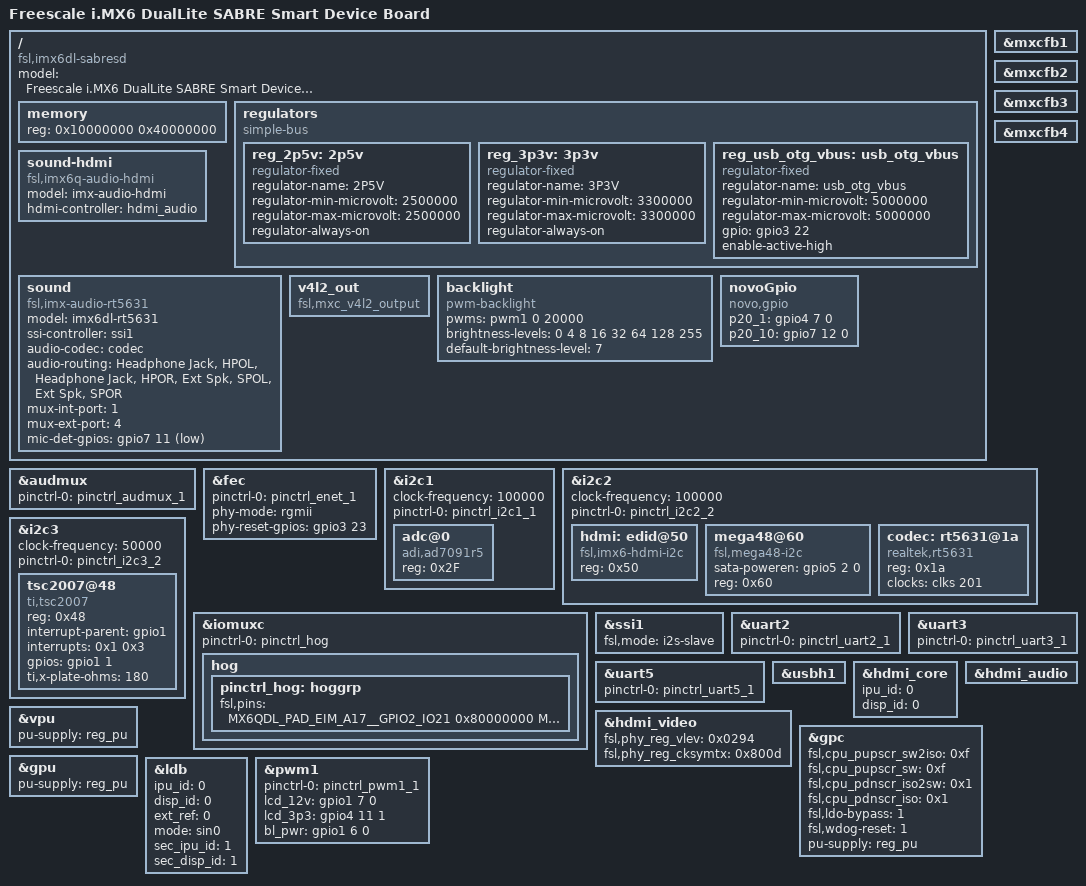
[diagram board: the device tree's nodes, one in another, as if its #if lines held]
/*
 * Copyright (C) 2013 Freescale Semiconductor, Inc.
 *
 * This program is free software; you can redistribute it and/or modify
 * it under the terms of the GNU General Public License version 2 as
 * published by the Free Software Foundation.
 */

/dts-v1/;

#include "hio-novo-dl.dtsi"
#include "hio-novo-qdl-sabresd.dtsi"

/ {
	model = "Freescale i.MX6 DualLite SABRE Smart Device Board";
	compatible = "fsl,imx6dl-sabresd", "fsl,imx6dl";

	memory {
		reg = <0x10000000 0x40000000>;
	};

        regulators {    
                compatible = "simple-bus";

                reg_2p5v: 2p5v {
                        compatible = "regulator-fixed";
                        regulator-name = "2P5V";
                        regulator-min-microvolt = <2500000>;
                        regulator-max-microvolt = <2500000>;
                        regulator-always-on;
                };

		reg_3p3v: 3p3v {
			compatible = "regulator-fixed";
			regulator-name = "3P3V";
			regulator-min-microvolt = <3300000>;
			regulator-max-microvolt = <3300000>;
			regulator-always-on;
		};

		reg_usb_otg_vbus: usb_otg_vbus {
			compatible = "regulator-fixed";
			regulator-name = "usb_otg_vbus";
			regulator-min-microvolt = <5000000>;
			regulator-max-microvolt = <5000000>;
			gpio = <&gpio3 22 0>;
			enable-active-high;
		};
	};
	sound-hdmi {
		compatible = "fsl,imx6q-audio-hdmi",
			     "fsl,imx-audio-hdmi";
		model = "imx-audio-hdmi";
		hdmi-controller = <&hdmi_audio>;
	};
	sound {
		compatible = "fsl,imx-audio-rt5631";
		model = "imx6dl-rt5631";
		ssi-controller = <&ssi1>;
		audio-codec = <&codec>;
		audio-routing =
			"Headphone Jack", "HPOL",
			"Headphone Jack", "HPOR",
			"Ext Spk", "SPOL",
			"Ext Spk", "SPOR";
			//"MICBIAS", "AMIC",
			//"IN3R", "MICBIAS",
			//"DMIC", "MICBIAS",
			//"DMICDAT", "DMIC";
		mux-int-port = <1>;
		mux-ext-port = <4>;
		/*hp-det-gpios = <&gpio7 8 1>;*/
		/*+++wwj begin 20150317@add mic detect*/
		#ifdef CONFIG_MIC_DEC
	              mic-det-gpios = <&gpio7 11 1>;
		#endif
		/*+++wwj end 20150317@add mic detect*/
	};
	/*
	sound {
		compatible = "fsl,imx6q-sabrelite-sgtl5000",
			     "fsl,imx-audio-sgtl5000";
		model = "imx6q-sabrelite-sgtl5000";
		ssi-controller = <&ssi1>;
		audio-codec = <&codec>;
		audio-routing =
			"MIC_IN", "Mic Jack",
			"Mic Jack", "Mic Bias",
			"Headphone Jack", "HP_OUT";
		mux-int-port = <1>;
		mux-ext-port = <4>;
	};
	*/
	v4l2_out {
		compatible = "fsl,mxc_v4l2_output";
		status = "okay";
	};
	backlight {
		compatible = "pwm-backlight";
		/*pwms = <&pwm1 0 5000000>;*/
		pwms = <&pwm1 0 20000>;
		brightness-levels = <0 4 8 16 32 64 128 255>;
		default-brightness-level = <7>;
	};

//+++MQ
	/*
    ds28e10 {
        compatible = "fsl,imx_ds28e10";
        status = "okay";
        ds28e10_io = <&gpio1 2 0>;
    };
	*/
//+++MQ

	//novo_gpio
    novoGpio {
        compatible = "novo,gpio";
        status = "okay";
    
        p20_1 = <&gpio4 7 0>;
		
		//out
		p20_10 = <&gpio7 12 0>;
	};
};

&audmux {
        status = "okay";
        pinctrl-names = "default";
        pinctrl-0 = <&pinctrl_audmux_1>;
};

&mxcfb1 {
        status = "okay";
};

&mxcfb2 {
        status = "okay";
};

&mxcfb3 {
        status = "okay";
};

&mxcfb4 {
        status = "okay";
};

#if 0
&ecspi1 {
	fsl,spi-num-chipselects = <1>;
	cs-gpios = <&gpio4 9 0>,
		    <&gpio4 10 0>;
	pinctrl-names = "default";
	pinctrl-0 = <&pinctrl_ecspi1_2>;
	status = "okay";

	flash: m25p80@0 {
		compatible = "sst,sst25vf016b";
		spi-max-frequency = <20000000>;
		reg = <0>;
	};
};
#endif

&fec {
	pinctrl-names = "default";
	pinctrl-0 = <&pinctrl_enet_1>;
	phy-mode = "rgmii";
	phy-reset-gpios = <&gpio3 23 0>;
	status = "okay";
};

&i2c1 {
	status = "okay";
	clock-frequency = <100000>;
	pinctrl-names = "default";
	pinctrl-0 = <&pinctrl_i2c1_1>;

	adc@0 {
		compatible = "adi,ad7091r5";
		reg = <0x2F>;
	};
};

&i2c2 {
	clock-frequency = <100000>;
	pinctrl-names = "default";
	pinctrl-0 = <&pinctrl_i2c2_2>;
	status = "okay";

	hdmi: edid@50 {
		compatible = "fsl,imx6-hdmi-i2c";
		reg = <0x50>;
	};

	mega48@60 {
		compatible = "fsl,mega48-i2c";
		sata-poweren=<&gpio5 2 0>;
		reg = <0x60>;
	};

	codec: rt5631@1a {
		  compatible = "realtek,rt5631";
		  //compatible = "realtek,alc5631";
		  reg = <0x1a>;
		  clocks = <&clks 201>;
	};
};

&i2c3 {
	status = "okay";
	clock-frequency = <50000>;
	pinctrl-names = "default";
	pinctrl-0 = <&pinctrl_i2c3_2>;

	tsc2007@48 {
    	compatible = "ti,tsc2007";
        reg = <0x48>;
		interrupt-parent = <&gpio1>;
		interrupts = <0x1 0x3>;
		gpios = <&gpio1 1 0>;
		ti,x-plate-ohms = <180>;
		//ti,x-plate-ohms = <400>; 

		//test
		//gpio1 = <&gpio4 7 0>;       
	};
};

&iomuxc {
	pinctrl-names = "default";
	pinctrl-0 = <&pinctrl_hog>;

	hog {
		pinctrl_hog: hoggrp {
			fsl,pins = <
				/* MAX17135 */
				MX6QDL_PAD_EIM_A17__GPIO2_IO21 0x80000000
				MX6QDL_PAD_EIM_D17__GPIO3_IO17 0x80000000
				MX6QDL_PAD_EIM_D20__GPIO3_IO20 0x80000000
				MX6QDL_PAD_EIM_A18__GPIO2_IO20 0x80000000
				MX6QDL_PAD_EIM_OE__GPIO2_IO25 0x80000000
				/* elan touch */
				MX6QDL_PAD_EIM_A20__GPIO2_IO18 0x80000000
				MX6QDL_PAD_EIM_DA8__GPIO3_IO08 0x80000000
				MX6QDL_PAD_GPIO_4__GPIO1_IO04  0x80000000
				/*MX6QDL_PAD_GPIO_1__GPIO1_IO01  0x170b0*/		
				/*MX6QDL_PAD_EIM_D24__UART3_TX_DATA 0x80000000 */
				/*MX6QDL_PAD_EIM_D25__UART3_RX_DATA 0x80000000 */
				/*+++ wangwenjing*/
				MX6QDL_PAD_EIM_A25__GPIO5_IO02 0x80000000
				MX6QDL_PAD_GPIO_1__GPIO1_IO01	0x80000000

				//ad rst
				MX6QDL_PAD_GPIO_3__GPIO1_IO03	0x80000000

				//p20
				MX6QDL_PAD_KEY_COL0__GPIO4_IO06	0x80000000			/*in-p20_1*/
				MX6QDL_PAD_KEY_COL1__GPIO4_IO08	0x80000000			/*in-p20_3*/
				MX6QDL_PAD_KEY_COL2__GPIO4_IO10 0x80000000          /*in-p20_5*/

				MX6QDL_PAD_GPIO_17__GPIO7_IO12	0x80000000			/*out-p20_10*/
				MX6QDL_PAD_CSI0_DAT18__GPIO6_IO04	0x80000000		/*out-p20_12*/				
				MX6QDL_PAD_CSI0_DAT8__GPIO5_IO26	0x80000000		/*out-p20_14*/

				MX6QDL_PAD_KEY_ROW0__GPIO4_IO07		0x80000000		/*in-p20_15*/
				MX6QDL_PAD_KEY_ROW1__GPIO4_IO09		0x80000000		/*in-p20_17*/
				MX6QDL_PAD_KEY_ROW2__GPIO4_IO11		0x80000000		/*in-p20_19*/
				
				MX6QDL_PAD_CSI0_DAT19__GPIO6_IO05	0x80000000		/*out-p20_20*/
				MX6QDL_PAD_CSI0_DAT9__GPIO5_IO27	0x80000000		/*out-p20_21*/
				MX6QDL_PAD_CSI0_DAT10__GPIO5_IO28	0x80000000		/*out-p20_22*/
				MX6QDL_PAD_CSI0_DAT11__GPIO5_IO29	0x80000000		/*out-p20_23*/
				
				//p24
				MX6QDL_PAD_GPIO_19__GPIO4_IO05		0x80000000		/*out-p24_5*/
				MX6QDL_PAD_GPIO_3__GPIO1_IO03		0x80000000		/*out-p24_6*/
				MX6QDL_PAD_GPIO_8__GPIO1_IO08		0x80000000		/*out-p24_8*/
			>;
		};
	};
};

&ssi1 {
	fsl,mode = "i2s-slave";
	status = "okay";
};

#if 0
&flexcan1 {
		pinctrl-names = "default";
		pinctrl-0 = <&pinctrl_flexcan1_1>;
		pinctrl-assert-gpios = <&max7310_b 3 GPIO_ACTIVE_HIGH>; /* TX */
		trx-en-gpio = <&max7310_b 6 GPIO_ACTIVE_HIGH>;
		trx-stby-gpio = <&max7310_b 5 GPIO_ACTIVE_HIGH>;
		status = "okay"; /* pin conflict with fec */
};
#endif

&uart2 {
	status = "okay";
	pinctrl-names = "default";
	pinctrl-0 = <&pinctrl_uart2_1>;
};

&uart3 {
	status = "okay";
	pinctrl-names = "default";
	pinctrl-0 = <&pinctrl_uart3_1>;
};

#if 0
&uart4 {
       status = "okay";
       pinctrl-names = "default";
       pinctrl-0 = <&pinctrl_uart4_1>;
};
#endif

&uart5 {
       status = "okay";
       pinctrl-names = "default";
       pinctrl-0 = <&pinctrl_uart5_1>;
};


&usbh1 {
	status = "okay";
};


&hdmi_core {
        ipu_id = <0>;
        disp_id = <0>;
        status = "okay";
};      
&hdmi_video {
        fsl,phy_reg_vlev = <0x0294>;
        fsl,phy_reg_cksymtx = <0x800d>;
        status = "okay";
/*pinctrl already defined in i2c2 pinctrl
        pinctrl-names = "default";
        pinctrl-0 = <&pinctrl_hdmi_hdcp_1>;
        fsl,hdcp; 
*/
};
&hdmi_audio {
        status = "okay";
};

/*---wangwenjing 20150611@delete for SATA_POWER_EN
&hdmi_cec {
        pinctrl-names = "default";
        pinctrl-0 = <&pinctrl_hdmi_cec_1>;
        status = "okay";
};
*/
&vpu {
	pu-supply = <&reg_pu>; /* ldo-bypass:use pu_dummy if VDDSOC share with VDDPU */
	status = "okay";
};
&gpc {
	fsl,cpu_pupscr_sw2iso = <0xf>;
	fsl,cpu_pupscr_sw = <0xf>;
	fsl,cpu_pdnscr_iso2sw = <0x1>;
	fsl,cpu_pdnscr_iso = <0x1>;
	fsl,ldo-bypass = <1>; /* use ldo-bypass, u-boot will check it and configure */
	fsl,wdog-reset = <1>; /* watchdog select of reset source */
	pu-supply = <&reg_pu>; /* ldo-bypass:use pu_dummy if VDDSOC share with VDDPU */
};

&gpu {
	pu-supply = <&reg_pu>; /* ldo-bypass:use pu_dummy if VDDSOC share with VDDPU */
};
&ldb {
	ipu_id = <0>;
	disp_id = <1>;/*snake edit*/
	disp_id = <0>;
	ext_ref = <1>;/*snake edit*/
	ext_ref = <0>;
	mode = "sep1"; /**/
	mode = "sin0"; 
	sec_ipu_id = <1>;
	sec_disp_id = <1>;
	status = "okay";
};

&pwm1 {
	pinctrl-names = "default";
	pinctrl-0 = <&pinctrl_pwm1_1>;
	lcd_12v = <&gpio1 7 0>;
              lcd_3p3 = <&gpio4 11 1>;
	bl_pwr = <&gpio1 6 0>;

	//ad rst
	//ad7091_rst = <&gpio1 3 0>;
 
	status = "okay";
};
